# CY8C5888LTI_LP097 register map
File version: 0.1
CY8C58LP
Registers are 8-bit, read-write, no defined reset value unless marked. A register's access mark holds for its fields unless they carry their own. Offsets are from the block's base; lines under a group give offsets from that group; [hi:lo] are bit positions; {n}, {i} and the like mark numbered series; 'fields as' and 'values as' point back to an identical list; <NAME> marks a mode.

## Memory map
0x00000000 PC — UART
0x00000000 GPS — UART
0x00000000 XB — UART

## PC — UART
Base 0x00000000
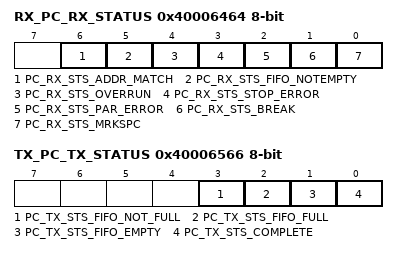
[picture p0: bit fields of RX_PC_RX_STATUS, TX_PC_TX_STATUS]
0x40006464 RX_PC_RX_STATUS — RX status register
  [6] PC_RX_STS_ADDR_MATCH ro, [5] PC_RX_STS_FIFO_NOTEMPTY ro, [4] PC_RX_STS_OVERRUN ro, [3] PC_RX_STS_STOP_ERROR ro, [2] PC_RX_STS_PAR_ERROR ro, [1] PC_RX_STS_BREAK ro, [0] PC_RX_STS_MRKSPC ro
0x40006527 RX_PC_RX_ADDRESS1 — RX Address1 Register
0x40006537 RX_PC_RX_ADDRESS2 — RX Address2 Register
0x40006545 TX_PC_TX_DATA — TX Data Register
0x40006547 RX_PC_RX_DATA — RX Data Register
0x40006566 TX_PC_TX_STATUS — TX status register
  [3] PC_TX_STS_FIFO_NOT_FULL ro, [2] PC_TX_STS_FIFO_FULL ro, [1] PC_TX_STS_FIFO_EMPTY ro, [0] PC_TX_STS_COMPLETE ro

## GPS — UART
Base 0x00000000
0x40006426 RX_GPS_RX_ADDRESS1 — RX Address1 Register
0x40006436 RX_GPS_RX_ADDRESS2 — RX Address2 Register
0x40006446 RX_GPS_RX_DATA — RX Data Register
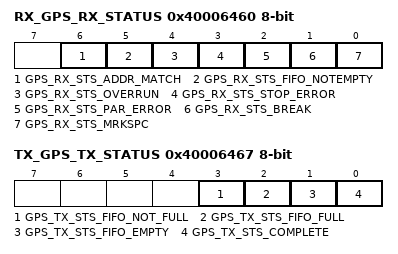
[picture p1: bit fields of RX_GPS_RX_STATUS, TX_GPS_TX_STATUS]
0x40006460 RX_GPS_RX_STATUS — RX status register
  [6] GPS_RX_STS_ADDR_MATCH ro, [5] GPS_RX_STS_FIFO_NOTEMPTY ro, [4] GPS_RX_STS_OVERRUN ro, [3] GPS_RX_STS_STOP_ERROR ro, [2] GPS_RX_STS_PAR_ERROR ro, [1] GPS_RX_STS_BREAK ro, [0] GPS_RX_STS_MRKSPC ro
0x40006467 TX_GPS_TX_STATUS — TX status register
  [3] GPS_TX_STS_FIFO_NOT_FULL ro, [2] GPS_TX_STS_FIFO_FULL ro, [1] GPS_TX_STS_FIFO_EMPTY ro, [0] GPS_TX_STS_COMPLETE ro
0x40006548 TX_GPS_TX_DATA — TX Data Register

## XB — UART
Base 0x00000000
0x40006422 RX_XB_RX_ADDRESS1 — RX Address1 Register
0x40006432 RX_XB_RX_ADDRESS2 — RX Address2 Register
0x40006442 RX_XB_RX_DATA — RX Data Register
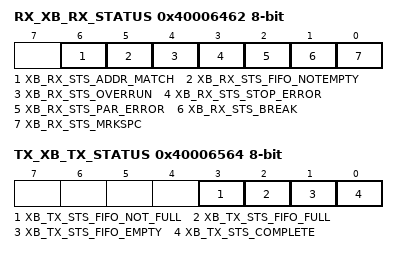
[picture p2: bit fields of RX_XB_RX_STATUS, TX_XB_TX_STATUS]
0x40006462 RX_XB_RX_STATUS — RX status register
  [6] XB_RX_STS_ADDR_MATCH ro, [5] XB_RX_STS_FIFO_NOTEMPTY ro, [4] XB_RX_STS_OVERRUN ro, [3] XB_RX_STS_STOP_ERROR ro, [2] XB_RX_STS_PAR_ERROR ro, [1] XB_RX_STS_BREAK ro, [0] XB_RX_STS_MRKSPC ro
0x40006544 TX_XB_TX_DATA — TX Data Register
0x40006564 TX_XB_TX_STATUS — TX status register
  [3] XB_TX_STS_FIFO_NOT_FULL ro, [2] XB_TX_STS_FIFO_FULL ro, [1] XB_TX_STS_FIFO_EMPTY ro, [0] XB_TX_STS_COMPLETE ro
